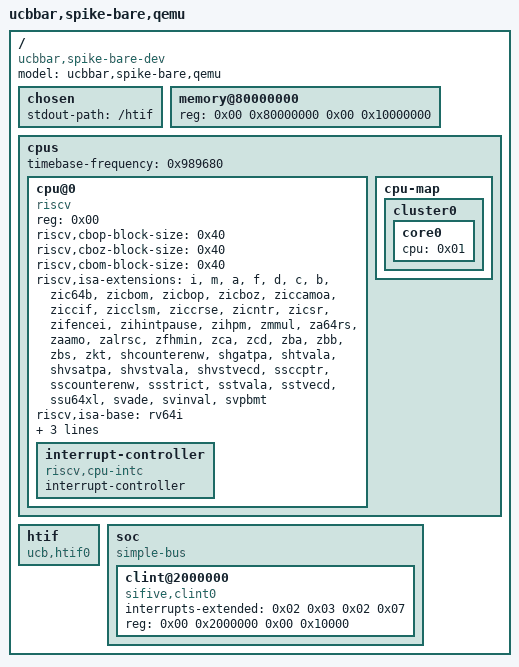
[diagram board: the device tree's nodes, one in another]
/dts-v1/;

/ {
	#address-cells = <0x02>;
	#size-cells = <0x02>;
	compatible = "ucbbar,spike-bare-dev";
	model = "ucbbar,spike-bare,qemu";

	chosen {
		stdout-path = "/htif";
	};

	memory@80000000 {
		device_type = "memory";
		reg = <0x00 0x80000000 0x00 0x10000000>;
	};

	cpus {
		#address-cells = <0x01>;
		#size-cells = <0x00>;
		timebase-frequency = <0x989680>;

		cpu@0 {
			phandle = <0x01>;
			device_type = "cpu";
			reg = <0x00>;
			status = "okay";
			compatible = "riscv";
			riscv,cbop-block-size = <0x40>;
			riscv,cboz-block-size = <0x40>;
			riscv,cbom-block-size = <0x40>;
			riscv,isa-extensions = "i", "m", "a", "f", "d", "c", "b", "zic64b", "zicbom", "zicbop", "zicboz", "ziccamoa", "ziccif", "zicclsm", "ziccrse", "zicntr", "zicsr", "zifencei", "zihintpause", "zihpm", "zmmul", "za64rs", "zaamo", "zalrsc", "zfhmin", "zca", "zcd", "zba", "zbb", "zbs", "zkt", "shcounterenw", "shgatpa", "shtvala", "shvsatpa", "shvstvala", "shvstvecd", "ssccptr", "sscounterenw", "ssstrict", "sstvala", "sstvecd", "ssu64xl", "svade", "svinval", "svpbmt";
			riscv,isa-base = "rv64i";
			riscv,isa = "rv64imafdcb_zic64b_zicbom_zicbop_zicboz_ziccamoa_ziccif_zicclsm_ziccrse_zicntr_zicsr_zifencei_zihintpause_zihpm_zmmul_za64rs_zaamo_zalrsc_zfhmin_zca_zcd_zba_zbb_zbs_zkt_sdtrig_shcounterenw_shgatpa_shtvala_shvsatpa_shvstvala_shvstvecd_ssccptr_sscounterenw_ssstrict_sstvala_sstvecd_ssu64xl_svade_svinval_svpbmt";
			mmu-type = "riscv,sv39";

			interrupt-controller {
				#interrupt-cells = <0x01>;
				interrupt-controller;
				compatible = "riscv,cpu-intc";
				phandle = <0x02>;
			};
		};

		cpu-map {

			cluster0 {

				core0 {
					cpu = <0x01>;
				};
			};
		};
	};

	htif {
		compatible = "ucb,htif0";
	};

	soc {
		#address-cells = <0x02>;
		#size-cells = <0x02>;
		compatible = "simple-bus";
		ranges;

		clint@2000000 {
			interrupts-extended = <0x02 0x03 0x02 0x07>;
			reg = <0x00 0x2000000 0x00 0x10000>;
			compatible = "sifive,clint0", "riscv,clint0";
		};
	};
};
